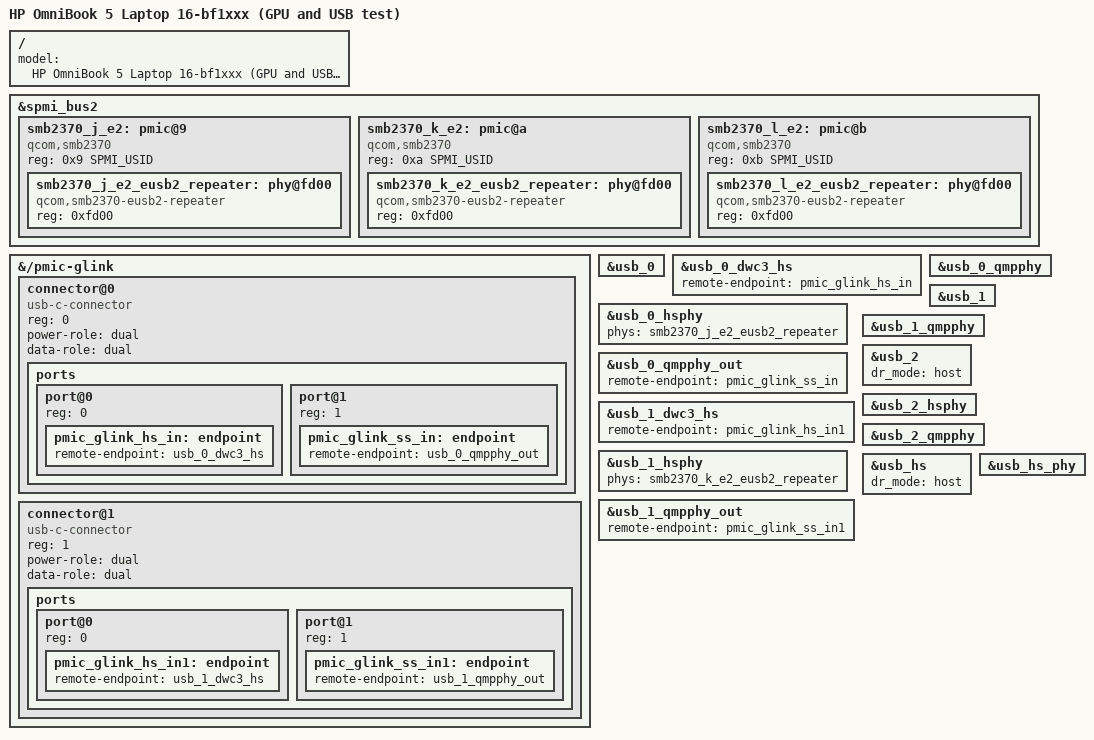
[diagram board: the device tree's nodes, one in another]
// SPDX-License-Identifier: BSD-3-Clause
/*
 * HP OmniBook 5 16-bf1xxx, USB test device tree: the GPU test device tree
 * plus the right-hand USB-A port (working since 2026-09-29) and the two
 * left-hand USB-C ports. Kept apart from the GPU test device tree until
 * it is proven. Booted by the GRUB entry "device tree (GPU and USB-A
 * test)".
 *
 * Evidence (HP DSDT and PEP, docs/usb-a-bringup-2026-09-29.md and
 * docs/usb-c-ports-2026-09-29.md):
 *
 * USB-A:
 * - \_SB.USB2 (QCOM0F9A) is the xHCI at 0x0a000000 with interrupts GIC SPI
 *   871 and 370: usb_2. Its root-hub ports return _UPC type 0x03, USB 3
 *   Standard-A, so the controller is host-only.
 * - Its PEP entry (LPCL) votes the usb30_tert and usb_2_phy GDSCs and the
 *   tcsr_usb2_4 / tcsr_usb4_2 reference clocks: usb_2 and its PHYs.
 *
 * USB-C:
 * - \_SB.URS0 (QCOM0F8B, dual-role, 0x0a600000) is usb_0 and \_SB.URS1
 *   (QCOM0F8C, 0x0a800000) is usb_1. Their ports use _PLD PLD0 and PLD1,
 *   the same as the UCSI connectors UCN0 and UCN1 (_UPC type 0x09,
 *   Type-C), which the firmware reports as connectors 1 and 2 (reg 0 and
 *   1 here). Connector 2 is the port away from the hinge (charging-watch,
 *   2026-09-29), so connector 1 is the one next to it. The UCSI device
 *   also lists UCN2, the USB-A port.
 * - Their PEP entries (LPCE, the Mahua branch) vote the usb30_prim /
 *   usb_0_phy and usb30_sec / usb_1_phy GDSCs.
 * - The connectors are wired as on the upstream Glymur laptops: high speed
 *   to the DWC3 controller, SuperSpeed to its QMP USB3/DP PHY, which is
 *   the orientation and mode switch that PMIC GLink's port notifications
 *   ask for before they are acknowledged. UCSI drives the data role
 *   through the controllers' usb-role-switch.
 *
 * Internal camera (from kernel -8, 2026-09-30,
 * docs/camera-usb-controller-2026-09-30.md):
 * - the camera is a USB device (HP True Vision FHD, USB\VID_30C9&PID_00D9
 *   under Windows) on \_SB.USB4 (QCOM0FEF): 0x0a200000, GIC SPI 240 and
 *   246 (ACPI 272, 278), one root-hub port. That is usb_hs, a
 *   high-speed-only DWC3 with its own M31 eUSB2 PHY; enabled here as host
 *   only.
 * - Its ACPI resources also name GPIO 9, whose role is unknown; it stays
 *   reserved and untouched. If firmware leaves the camera unpowered, it
 *   simply does not enumerate.
 *
 * Not declared yet, for all four controllers:
 * - PHY supplies. HP's PEP names the rails (usb_2: S7F, L15B, L4C, L7B,
 *   L4F, L1C, L2F, L1F; usb_0: S7F, L15B, L3F, L7B, L4H; usb_1: the same
 *   plus L1H), but this device tree has no RPMh regulators yet and the
 *   per-supply mapping is not evidenced. The rails stay as firmware left
 *   them; the PHY drivers get dummy regulators.
 *
 * eUSB2 repeaters (from kernel -8, 2026-09-30): high speed works on all
 * three ports but full and low speed fail on all three (a USB mouse, error
 * -71). On the ACPI boot, where Linux leaves the PHY as firmware set it,
 * the USB-A port ran a Dell receiver at 12 Mb/s (full speed). An eUSB2 PHY
 * reaches a USB 2 connector only through a repeater, and the Linux
 * repeater driver puts it in host mode (it forces the repeater's 19.2 MHz
 * clock on, an eUSB 1.2 workaround); without a repeater node that never
 * happens. HP's ACPI does not describe the repeaters (Windows' PMIC
 * driver and firmware own them; the PHYC tuning methods are empty for
 * usb_0 and usb_1), so:
 * - placement follows Qualcomm's Mahua/Glymur CRD (smb2370.dtsi): SMB2370
 *   PMICs on SPMI bus 2 at SID 9 (usb_0) and SID 10 (usb_1), repeater at
 *   0xfd00;
 * - HP's PEP votes for usb_0 and usb_1 include L15B 1.8 V and L7B
 *   3.072 V, the rails the CRD gives these repeaters (vdd18, vdd3);
 * - patches/kernel/upstream/qcom-next/0003 makes the repeater driver
 *   check that the PMIC at that SID reports the SMB2370 subtype before
 *   anything writes to it. If not, it refuses: then the USB-C ports lose
 *   data for that boot (their PHYs wait for the repeater), but nothing is
 *   written to the wrong PMIC. Charging does not depend on it.
 * - SID 11 (the CRD's third, disabled, SMB2370) is declared only to be
 *   identified: its repeater is linked to nothing, so it is never
 *   initialized. usb_2 (USB-A, which also votes L15B and L7B) stays
 *   without a repeater until that is known.
 * - HP's USB3 PHY tuning for usb_2 (\_SB.USB2.PHYC, two register writes).
 * - DisplayPort alternate mode (mdss_dp0/dp1 stay disabled).
 */
/dts-v1/;

#include "mahua-hp-omnibook-5-bf1xxx-gpu.dts"

/ {
	model = "HP OmniBook 5 Laptop 16-bf1xxx (GPU and USB test)";
};

&spmi_bus2 {
	smb2370_j_e2: pmic@9 {
		compatible = "qcom,smb2370", "qcom,spmi-pmic";
		reg = <0x9 SPMI_USID>;
		#address-cells = <1>;
		#size-cells = <0>;

		smb2370_j_e2_eusb2_repeater: phy@fd00 {
			compatible = "qcom,smb2370-eusb2-repeater";
			reg = <0xfd00>;
			#phy-cells = <0>;
		};
	};

	smb2370_k_e2: pmic@a {
		compatible = "qcom,smb2370", "qcom,spmi-pmic";
		reg = <0xa SPMI_USID>;
		#address-cells = <1>;
		#size-cells = <0>;

		smb2370_k_e2_eusb2_repeater: phy@fd00 {
			compatible = "qcom,smb2370-eusb2-repeater";
			reg = <0xfd00>;
			#phy-cells = <0>;
		};
	};

	/* Identification only: linked to no PHY, never initialized */
	smb2370_l_e2: pmic@b {
		compatible = "qcom,smb2370", "qcom,spmi-pmic";
		reg = <0xb SPMI_USID>;
		#address-cells = <1>;
		#size-cells = <0>;

		smb2370_l_e2_eusb2_repeater: phy@fd00 {
			compatible = "qcom,smb2370-eusb2-repeater";
			reg = <0xfd00>;
			#phy-cells = <0>;
		};
	};
};

&{/pmic-glink} {
	/* Next to the hinge */
	connector@0 {
		compatible = "usb-c-connector";
		reg = <0>;
		power-role = "dual";
		data-role = "dual";

		ports {
			#address-cells = <1>;
			#size-cells = <0>;

			port@0 {
				reg = <0>;

				pmic_glink_hs_in: endpoint {
					remote-endpoint = <&usb_0_dwc3_hs>;
				};
			};

			port@1 {
				reg = <1>;

				pmic_glink_ss_in: endpoint {
					remote-endpoint = <&usb_0_qmpphy_out>;
				};
			};
		};
	};

	/* Away from the hinge */
	connector@1 {
		compatible = "usb-c-connector";
		reg = <1>;
		power-role = "dual";
		data-role = "dual";

		ports {
			#address-cells = <1>;
			#size-cells = <0>;

			port@0 {
				reg = <0>;

				pmic_glink_hs_in1: endpoint {
					remote-endpoint = <&usb_1_dwc3_hs>;
				};
			};

			port@1 {
				reg = <1>;

				pmic_glink_ss_in1: endpoint {
					remote-endpoint = <&usb_1_qmpphy_out>;
				};
			};
		};
	};
};

&usb_0 {
	status = "okay";
};

&usb_0_dwc3_hs {
	remote-endpoint = <&pmic_glink_hs_in>;
};

&usb_0_hsphy {
	phys = <&smb2370_j_e2_eusb2_repeater>;

	status = "okay";
};

&usb_0_qmpphy {
	status = "okay";
};

&usb_0_qmpphy_out {
	remote-endpoint = <&pmic_glink_ss_in>;
};

&usb_1 {
	status = "okay";
};

&usb_1_dwc3_hs {
	remote-endpoint = <&pmic_glink_hs_in1>;
};

&usb_1_hsphy {
	phys = <&smb2370_k_e2_eusb2_repeater>;

	status = "okay";
};

&usb_1_qmpphy {
	status = "okay";
};

&usb_1_qmpphy_out {
	remote-endpoint = <&pmic_glink_ss_in1>;
};

&usb_2 {
	dr_mode = "host";
	/delete-property/ usb-role-switch;

	status = "okay";
};

&usb_2_hsphy {
	status = "okay";
};

&usb_2_qmpphy {
	status = "okay";
};

&usb_hs {
	dr_mode = "host";
	/delete-property/ usb-role-switch;

	status = "okay";
};

&usb_hs_phy {
	status = "okay";
};
